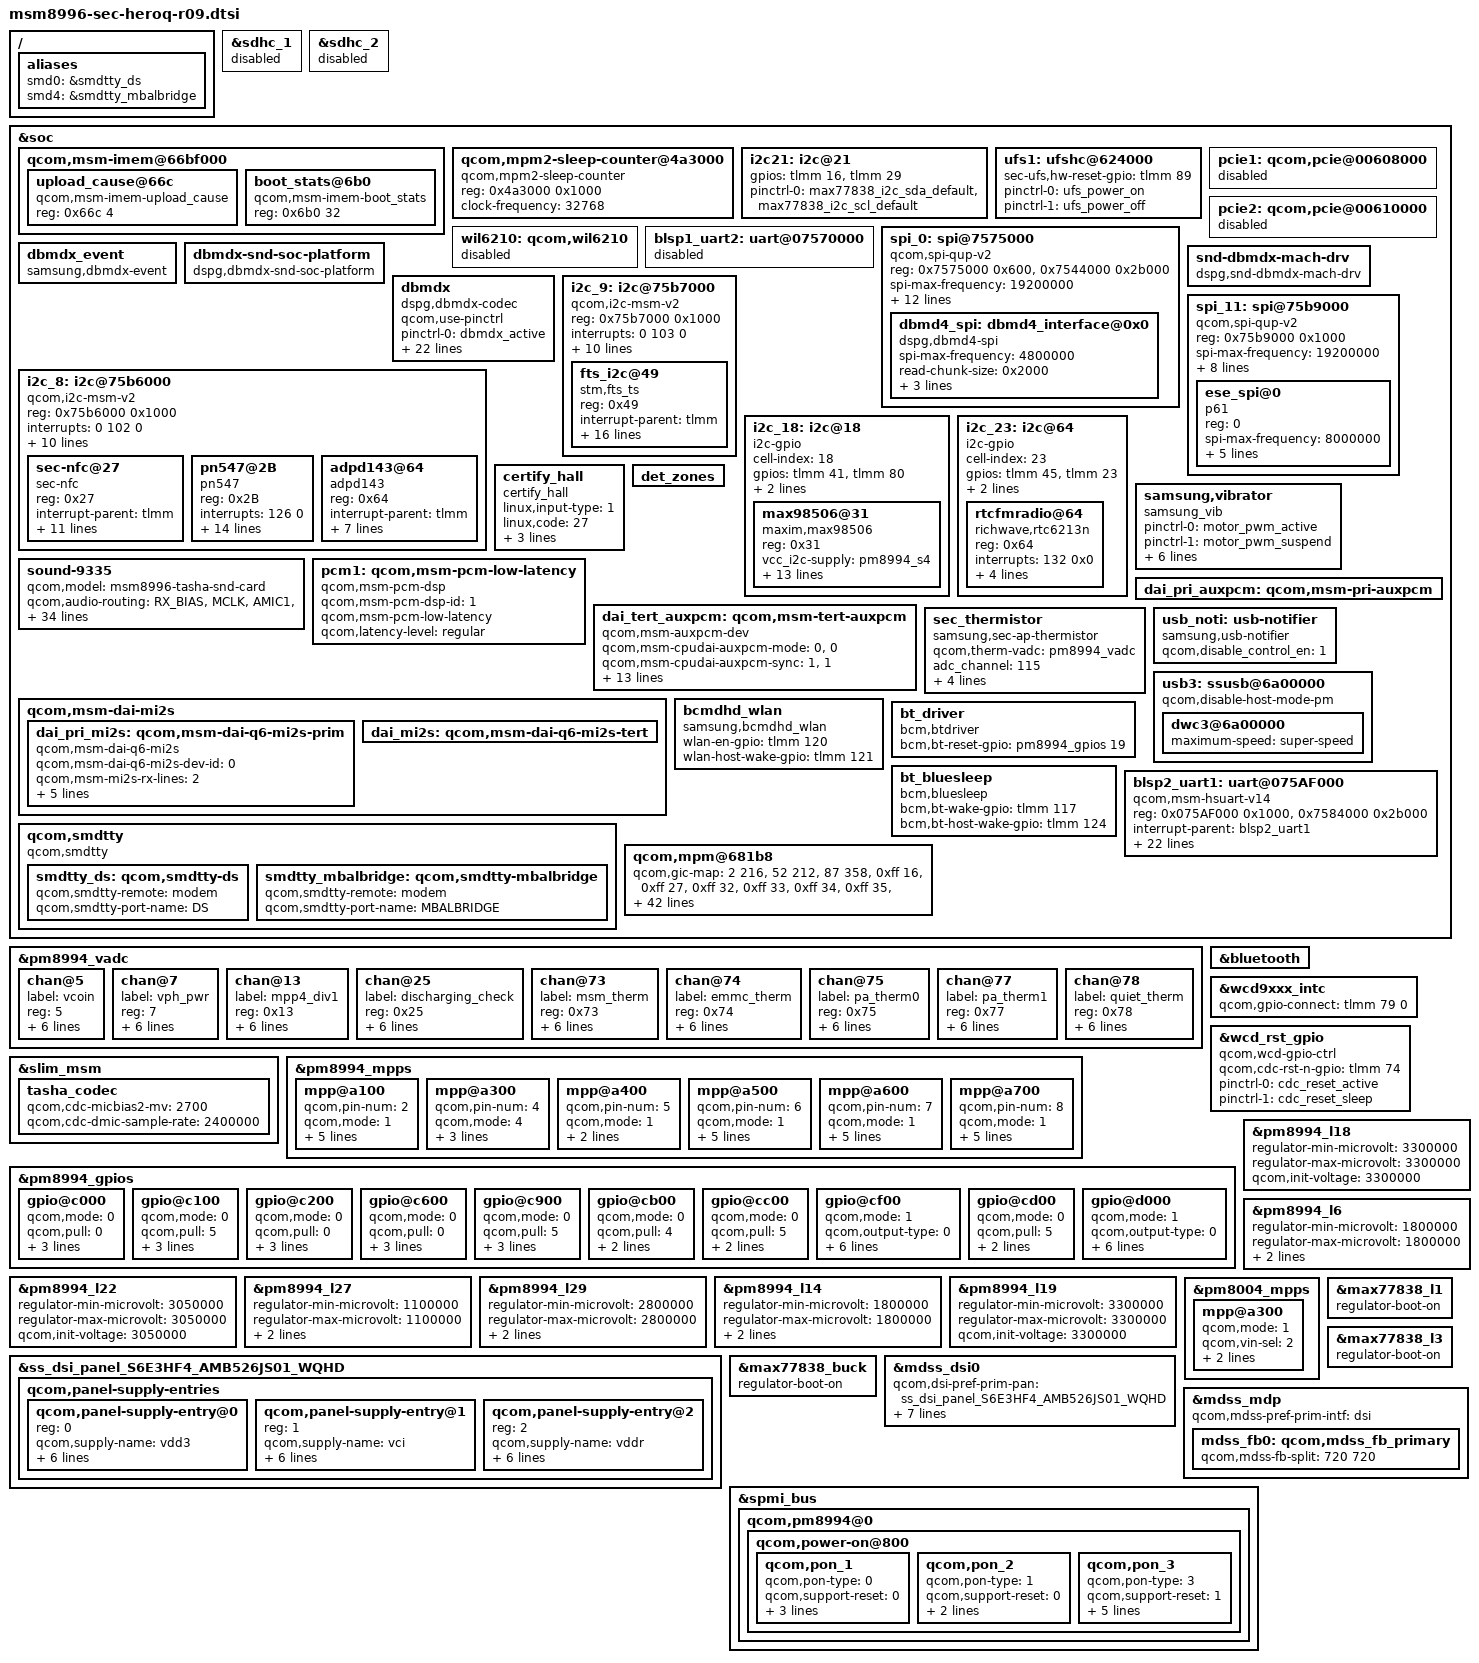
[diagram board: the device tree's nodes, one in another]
/* Copyright (c) 2015, The Linux Foundation. All rights reserved.
 *
 * This program is free software; you can redistribute it and/or modify
 * it under the terms of the GNU General Public License version 2 and
 * only version 2 as published by the Free Software Foundation.
 *
 * This program is distributed in the hope that it will be useful,
 * but WITHOUT ANY WARRANTY; without even the implied warranty of
 * MERCHANTABILITY or FITNESS FOR A PARTICULAR PURPOSE.  See the
 * GNU General Public License for more details.
 */

/*
 * As a general rule, only chipset-specific property overrides should be placed
 * inside this file.
 */

/*
 * Implement here Samsung specific dtsi
 */

#include "msm8996-pinctrl-sec-heroq-r09.dtsi"
#include "msm8996-sec-heroq-battery-r09.dtsi"
#include "msm8996-heroq_fingerprint-sensor_03.dtsi"
#include "msm8996-max77854-heroqlte.dtsi"
#include "msm8996-camera-sensor-heroq-r04.dtsi"
#include "msm8996-heroqlte-mst-r09.dtsi"
/{

	aliases {
		/* smdtty devices */
		smd0 = &smdtty_ds;
		smd4 = &smdtty_mbalbridge;
	};

};
&sdhc_1 {
	status = "disabled";
};
&sdhc_2 {
	status = "disabled";
};

&soc {
	qcom,msm-imem@66bf000 {

		upload_cause@66c { /* CONFIG_SEC_DEBUG */
			compatible = "qcom,msm-imem-upload_cause";
			reg = <0x66c 4>;
		};

		boot_stats@6b0 {
			compatible = "qcom,msm-imem-boot_stats";
			reg = <0x6b0 32>;
		};
	};

	qcom,mpm2-sleep-counter@4a3000 {
		compatible = "qcom,mpm2-sleep-counter";
		reg = <0x4a3000 0x1000>;
		clock-frequency = <32768>;
	};

	/* MAX77838 Display PMIC(PB38) */
	i2c21: i2c@21 {
		gpios = <&tlmm 16 0 /* sda */
			&tlmm 29 0 /* scl */
		>;

		pinctrl-names = "max77838_i2c_pins_default";
		pinctrl-0 = <&max77838_i2c_sda_default &max77838_i2c_scl_default>;
	};

	ufs1: ufshc@624000 {
		sec-ufs,hw-reset-gpio = <&tlmm 89 0x0>;
		pinctrl-names = "ufs_poweron","ufs_poweroff";
		pinctrl-0 = <&ufs_power_on>;
		pinctrl-1 = <&ufs_power_off>;
	};

	pcie1: qcom,pcie@00608000 {
		status = "disabled";
	};

	pcie2: qcom,pcie@00610000 {
		status = "disabled";
	};

	wil6210: qcom,wil6210 {
		status = "disabled";
	};

	blsp1_uart2: uart@07570000 {
		status = "disabled";
	};

	spi_0: spi@7575000 { /* BLSP1 QUP0 */
		compatible = "qcom,spi-qup-v2";
		#address-cells = <1>;
		#size-cells = <0>;
		reg-names = "spi_physical", "spi_bam_physical";
		reg = <0x7575000 0x600>,<0x7544000 0x2b000>;
		spi-max-frequency = <19200000>;
		interrupt-names = "spi_irq", "spi_bam_irq";
		interrupts = <0 95 0>,<0 238 0>;
		qcom,master-id = <86>;
		qcom,use-bam;
		qcom,infinite-mode = <0>;

		qcom,bam-consumer-pipe-index = <12>;
		qcom,bam-producer-pipe-index = <13>;


		qcom,ver-reg-exists;
		qcom,use-pinctrl;
		pinctrl-names = "spi_default", "spi_sleep";
		pinctrl-0 = <&spi_0_active>;
		pinctrl-1 = <&spi_0_sleep>;

		clock-names = "iface_clk", "core_clk";

		clocks = <&clock_gcc clk_gcc_blsp1_ahb_clk>,
			 <&clock_gcc clk_gcc_blsp1_qup1_spi_apps_clk>;

		dbmd4_spi:dbmd4_interface@0x0  {
			compatible = "dspg,dbmd4-spi";
			spi-max-frequency = <4800000>;
			read-chunk-size  = <0x2000> ;
			write-chunk-size = <0x20000> ;
			dma_min_buffer_size = <0>;
			reg = <0>;
		};
	};

	dbmdx_event {
		status = "okay";
		compatible = "samsung,dbmdx-event";
	};

	dbmdx-snd-soc-platform {
		compatible = "dspg,dbmdx-snd-soc-platform";
	};

	snd-dbmdx-mach-drv {
		compatible = "dspg,snd-dbmdx-mach-drv";
	};

	dbmdx {
		status = "okay";
		compatible = "dspg,dbmdx-codec";

		qcom,use-pinctrl;
		pinctrl-names = "dbmdx_default", "dbmdx_sleep";
		pinctrl-0 = <&dbmdx_active>;
		pinctrl-1 = <&dbmdx_sleep>;

		sv-gpio = <&tlmm 42 0>; /* VOICE_INT */
		wakeup-gpio = <&pm8994_mpps 7 0>; /* VOICE_WAKE */
		reset-gpio = <&pm8004_mpps 4 0>; /* VOICE_RST */

		vreg_l27-supply = <&pm8994_l27>;

		auto_buffering = <1>;
		cmd-interface = <&dbmd4_spi>;
		feature-va; /* enable VA */
		/* feature-vqe; */ /* enable VQE */
		/* feature-firmware-overlay; */
		va-firmware-name = "dbmd4_va_fw.bin";
		/* vqe-firmware-name = "dbmd4_vqe_fw.bin"; */
		va-config = <0x80290020
					0x802210E0
					0x80158E8E
					0x801b0020
					0x80230021
					0x80103015>;
		va-speeds = <0x0000 460800   0 960000
					0x0000 2000000 0 4800000
					0x0000 3000000 0 4800000>;
		va-mic-config = <0xf041 0x1044 0x0008>;
		va-mic-mode = <0>;
		/* vqe-config = < >; */
		/* vqe-modes = <0 1 2 3 4 5 0x100>; */
		master-clk-rate = <32768>;
		/* constant-clk-rate = <32768>; */
		auto_detection = <1>;
		detection_buffer_channels = <0>;
		pcm_streaming_mode = <1>;
		firmware_id = <0xdbd4>;
		use_gpio_for_wakeup = <1>; /* Use wakeup gpio */
		wakeup_set_value = <0>;  /* Value to write to wakeup gpio */

	};
/*
	i2c_3: i2c@7577000 { // BLSP1 QUP3
		compatible = "qcom,i2c-msm-v2";
		#address-cells = <1>;
		#size-cells = <0>;
		reg-names = "qup_phys_addr";
		reg = <0x7577000 0x1000>;
		interrupt-names = "qup_irq";
		interrupts = <0 97 0>;
		dmas = <&dma_blsp1 16 32 0x20000020 0x20>,    // or 32 to 64
			<&dma_blsp1 17 32 0x20000020 0x20>;
		dma-names = "tx", "rx";
		qcom,master-id = <86>;
		qcom,clk-freq-out = <400000>;
		qcom,clk-freq-in  = <19200000>;
		clock-names = "iface_clk", "core_clk";
		clocks = <&clock_gcc clk_gcc_blsp1_ahb_clk>,
			<&clock_gcc clk_gcc_blsp1_qup3_i2c_apps_clk>;
		pinctrl-names = "i2c_active", "i2c_sleep";
		pinctrl-0 = <&i2c_3_active>;
		pinctrl-1 = <&i2c_3_sleep>;
		qcom,disable-dma;
	};
*/
	i2c_9: i2c@75b7000 { /* BLSP1 QUP9 */
		compatible = "qcom,i2c-msm-v2";
		#address-cells = <1>;
		#size-cells = <0>;
		reg-names = "qup_phys_addr";
		reg = <0x75b7000 0x1000>;
		interrupt-names = "qup_irq";
		interrupts = <0 103 0>;
		dmas = <&dma_blsp2 16 32 0x20000020 0x20>,    // or 32 to 64
		<&dma_blsp2 17 32 0x20000020 0x20>;
		dma-names = "tx", "rx";
		qcom,master-id = <84>;
		qcom,clk-freq-out = <400000>;
		qcom,clk-freq-in  = <19200000>;
		clock-names = "iface_clk", "core_clk";
		clocks = <&clock_gcc clk_gcc_blsp2_ahb_clk>,
		<&clock_gcc clk_gcc_blsp2_qup3_i2c_apps_clk>;
		pinctrl-names = "i2c_active", "i2c_sleep";
		pinctrl-0 = <&i2c_9_active>;
		pinctrl-1 = <&i2c_9_sleep>;
		qcom,disable-dma;
	};

	/* NFC */
	i2c_8: i2c@75b6000 { /* BLSP2 QUP1 */
		compatible = "qcom,i2c-msm-v2";
		#address-cells = <1>;
		#size-cells = <0>;
		reg-names = "qup_phys_addr";
		reg = <0x75b6000 0x1000>;
		interrupt-names = "qup_irq";
		interrupts = <0 102 0>;
		dmas = <&dma_blsp2 14 32 0x20000020 0x20>,
			<&dma_blsp2 15 32 0x20000020 0x20>;
		dma-names = "tx", "rx";
		qcom,master-id = <84>;
		qcom,clk-freq-out = <400000>;
		qcom,clk-freq-in  = <19200000>;
		clock-names = "iface_clk", "core_clk";
		clocks = <&clock_gcc clk_gcc_blsp2_ahb_clk>,
			<&clock_gcc clk_gcc_blsp2_qup2_i2c_apps_clk>;
		pinctrl-names = "i2c_active", "i2c_sleep";
		pinctrl-0 = <&i2c_8_active>;
		pinctrl-1 = <&i2c_8_sleep>;
		qcom,disable-dma;

		sec-nfc@27 {
			compatible = "sec-nfc";
			reg = <0x27>;
			interrupt-parent = <&tlmm>;
			interrupts = <126 0>;
			pinctrl-names = "nfc_active","nfc_suspend";
			pinctrl-0 = <&nfc_int_active &nfc_enable_active &nfc_firmware_active>;
			pinctrl-1 = <&nfc_int_suspend &nfc_enable_suspend &nfc_firmware_suspend>;
			sec-nfc,ven-gpio = <&tlmm 62 0x0>;
			sec-nfc,firm-gpio = <&tlmm 63 0x0>;
			sec-nfc,irq-gpio = <&tlmm 126 0x01>;
			clocks = <&clock_gcc clk_bb_clk2_pin>;
			clock-names = "nfc_clock";
			sec-nfc,i2c_1p8 = <&pm8994_l6>;
			qcom,clk-src="BBCLK2";
		};
		pn547@2B {
			compatible = "pn547";
			reg = <0x2B>;

			interrupts = <126 0>;
			interrupt-parent = <&tlmm>;

			pinctrl-names = "nfc_active","nfc_suspend";
			pinctrl-0 = <&nfc_int_active &nfc_enable_active &nfc_firmware_active>;
			pinctrl-1 = <&nfc_int_suspend &nfc_enable_suspend &nfc_firmware_suspend>;

			pn547,ven-gpio = <&tlmm 62 0x0>;
			pn547,firm-gpio = <&tlmm 63 0x0>;
			pn547,irq-gpio = <&tlmm 126 0x01>;
			pn547,clk_req-gpio = <&pm8994_gpios 10 0>;
			pn547,pwr_req = <&pm8994_mpps 6 0>;
			pn547,i2c_1p8 = <&pm8994_l6>;
			pn547,ldo_flag = <1>;
			clocks = <&clock_gcc clk_bb_clk2_pin>;
			clock-names = "nfc_clock";
			qcom,clk-src="BBCLK2";
		};
		adpd143@64 {
			compatible = "adpd143";
			reg = <0x64>;
			interrupt-parent = <&tlmm>;
			interrupts = <119 0>;
			pinctrl-names = "sleep", "idle";
			pinctrl-0 = <&hrm_int_suspend>;
			pinctrl-1 = <&hrm_int_active>;
			adpd143,irq_gpio = <&tlmm 119 0x00>;
			adpd143_1p8-supply = <&pm8994_lvs1>;
			adpd143_3p3-supply = <&pm8994_l19>;
			adpd143,use-sub-pmic = <0>;
		};
	};

	spi_11: spi@75b9000 { /* BLSP2 QUP4 */
		compatible = "qcom,spi-qup-v2";
		#address-cells = <1>;
		#size-cells = <0>;
		reg-names = "spi_physical";
		reg = <0x75b9000 0x1000>;
		spi-max-frequency = <19200000>;
		interrupt-names = "spi_irq";
		interrupts = <0 105 0>;
		qcom,master-id = <84>;

		qcom,ver-reg-exists;
		qcom,use-pinctrl;
		pinctrl-names = "spi_default", "spi_sleep";
		pinctrl-0 = <&spi_11_active>;
		pinctrl-1 = <&spi_11_sleep>;

		clock-names = "iface_clk", "core_clk";

		clocks = <&clock_gcc clk_gcc_blsp2_ahb_clk>,
			 <&clock_gcc clk_gcc_blsp2_qup5_spi_apps_clk>;
	    ese_spi@0 {
			compatible = "p61";
		    reg = <0>;
		    spi-max-frequency = <8000000>;

		    gpio-controller;
		    #gpio-cells = <2>;

		    p61-mosipin = <&tlmm 58 0x0>;
		    p61-misopin = <&tlmm 59 0x0>;
		    p61-cspin = <&tlmm 60 0x0>;
		    p61-clkpin = <&tlmm 61 0x0>;

		};
	};

	i2c_18: i2c@18 { /* max98506 amp */
		cell-index = <18>;
		compatible = "i2c-gpio";
		gpios = <&tlmm 41 0 /* sda */
			&tlmm 80 0 /* scl */
		>;
		i2c-gpio,delay-us = <2>;
		#address-cells = <1>;
		#size-cells = <0>;
		pinctrl-names = "default";
		pinctrl-0 = <&max98506_i2c_default>;

		max98506@31 {
			compatible = "maxim,max98506";
			reg = <0x31>;
			vcc_i2c-supply = <&pm8994_s4>;
			maxim,i2c-pull-up;
			maxim,platform_type = <1>;
			maxim,spk-gain= <0x14>;
			maxim,sysclk = <12288000>;
			maxim,vmon_slot = <1>;
			maxim,irq-gpio = <&pm8994_gpios 14 0x1>;
			maxim,platform_info = <1 0x1000 0x10001062 0x0FF1020B 0x00000000 41>;
			maxim,boost_step = <
				0x0F 0x0F 0x0F 0x0F
				0x0F 0x0F 0x0F 0x0F
				0x0F 0x0F 0x0F 0x0F
				0x0F 0x0F 0x02 0x00
			>;
			maxim,adc_threshold = <7>;
			maxim,registers-of-amp =
				<0x1F 0x00>,
				<0x21 0xC0>,
				<0x2F 0x00>;
		};
	};

	i2c_23: i2c@64{ /* FM Radio (Richwave) */
		cell-index = <23>;
		compatible = "i2c-gpio";

		gpios = <&tlmm 45 0 /* sda */
			&tlmm 23 0 /* scl */
		>;
		i2c-gpio,delay-us = <2>;
		#address-cells = <1>;
		#size-cells = <0>;
		status = "okay";
		pinctrl-names = "default";
		pinctrl-0 = <&fmradio_i2c_default>;

		rtcfmradio@64 {
			compatible = "richwave,rtc6213n", "rtc6213n";
			reg = <0x64>;
			interrupts = <132 0x0>;
			interrupt-parent = <&tlmm>;
			pinctrl-names = "default";
			pinctrl-0 = <&fmradio_int_active &fmradio_int_suspend>;
			fmint-gpio = <&tlmm 132 0>; /* FM_INT */
		};
	};

	certify_hall {
		compatible = "certify_hall";
		linux,input-type = <1>;
		linux,code = <27>;
		certify_hall,gpio_certify_cover = <&pm8994_gpios 7 0x1>;
		debounce-interval = <15>;
	};

	samsung,vibrator {
		compatible = "samsung_vib";
		pinctrl-names = "tlmm_motor_active","tlmm_motor_suspend";
		pinctrl-0 = <&motor_pwm_active>;
		pinctrl-1 = <&motor_pwm_suspend>;
		samsung,vib_pwm = <&tlmm 57 0>;
		samsung,gp_clk = <0x00364000>;   // Address of GP1 clock
		samsung,chip_model = <0>;         // using max77854 driver
		samsung,m_default = <2>;
		samsung,n_default = <92>;
		samsung,motor_strength = <94>;
		status = "ok";
	};

	det_zones: det_zones {
		#list-det-cells = <2>;
	};

	sound-9335 {
		qcom,model = "msm8996-tasha-snd-card";

		qcom,audio-routing =
			"RX_BIAS", "MCLK",
			"AMIC1", "MIC BIAS4",
			"MIC BIAS4", "Third Mic",
			"AMIC2", "MIC BIAS2",
			"MIC BIAS2", "Headset Mic",
			"AMIC3", "MIC BIAS2",
			"MIC BIAS2", "FM Tx",
			"DMIC0", "MIC BIAS1",
			"MIC BIAS1", "Digital Mic0",
			"DMIC2", "MIC BIAS3",
			"MIC BIAS3", "Digital Mic2";

		qcom,msm-mbhc-hphl-swh = <1>;
		qcom,msm-mbhc-gnd-swh = <1>;
		qcom,mpp-channel-scaling = <4 1 1>;
		qcom,det_debounce_time_ms = <100>;
		qcom,earjack-read-vadc = <&pm8994_vadc>;

		asoc-cpu = <&dai_pri_auxpcm>, <&dai_tert_auxpcm>, <&dai_pri_mi2s>, <&dai_mi2s>,
				<&sb_0_rx>, <&sb_0_tx>, <&sb_1_rx>, <&sb_1_tx>,
				<&sb_2_rx>, <&sb_2_tx>, <&sb_3_rx>, <&sb_3_tx>,
				<&sb_4_rx>, <&sb_4_tx>, <&sb_5_tx>, <&afe_pcm_rx>,
				<&afe_pcm_tx>, <&afe_proxy_rx>, <&afe_proxy_tx>,
				<&incall_record_rx>, <&incall_record_tx>,
				<&incall_music_rx>, <&incall_music2_rx>,
				<&sb_5_rx>;
		asoc-cpu-names = "msm-dai-q6-auxpcm.1", "msm-dai-q6-auxpcm.3",
				"msm-dai-q6-mi2s.0", "msm-dai-q6-mi2s.2",
				"msm-dai-q6-dev.16384", "msm-dai-q6-dev.16385",
				"msm-dai-q6-dev.16386", "msm-dai-q6-dev.16387",
				"msm-dai-q6-dev.16388", "msm-dai-q6-dev.16389",
				"msm-dai-q6-dev.16390", "msm-dai-q6-dev.16391",
				"msm-dai-q6-dev.16392", "msm-dai-q6-dev.16393",
				"msm-dai-q6-dev.16395", "msm-dai-q6-dev.224",
				"msm-dai-q6-dev.225", "msm-dai-q6-dev.241",
				"msm-dai-q6-dev.240", "msm-dai-q6-dev.32771",
				"msm-dai-q6-dev.32772", "msm-dai-q6-dev.32773",
				"msm-dai-q6-dev.32770", "msm-dai-q6-dev.16394";

		det-zones-list = <&det_zones 0 2>,
				 <&det_zones 690 2>,
				 <&det_zones 691 1>,
				 <&det_zones 9999 1>;

		/delete-property/qcom,hdmi-audio-rx;
		/delete-property/qcom,hph-en0-gpio;
		/delete-property/qcom,us-euro-gpios;
		/delete-property/qcom,wsa-max-devs;
		/delete-property/qcom,wsa-devs;
		/delete-property/qcom,wsa-aux-dev-prefix;
	};

	pcm1: qcom,msm-pcm-low-latency {
		compatible = "qcom,msm-pcm-dsp";
		qcom,msm-pcm-dsp-id = <1>;
		qcom,msm-pcm-low-latency;
		qcom,latency-level = "regular";
	};

	dai_pri_auxpcm: qcom,msm-pri-auxpcm {
		/delete-property/ pinctrl-names;
		/delete-property/ pinctrl-0;
		/delete-property/ pinctrl-1;
	};

	dai_tert_auxpcm: qcom,msm-tert-auxpcm {
		compatible = "qcom,msm-auxpcm-dev";
		qcom,msm-cpudai-auxpcm-mode = <0>, <0>;
		qcom,msm-cpudai-auxpcm-sync = <1>, <1>;
		qcom,msm-cpudai-auxpcm-frame = <5>, <4>;
		qcom,msm-cpudai-auxpcm-quant = <2>, <2>;
		qcom,msm-cpudai-auxpcm-num-slots = <1>, <1>;
		qcom,msm-cpudai-auxpcm-slot-mapping = <1>, <1>;
		qcom,msm-cpudai-auxpcm-data = <0>, <0>;
		qcom,msm-cpudai-auxpcm-pcm-clk-rate = <2048000>, <2048000>;
		qcom,msm-auxpcm-interface = "tertiary";
		qcom,msm-cpudai-afe-clk-ver = <2>;
		pinctrl-names = "default", "sleep";
		pinctrl-0 = <&tert_aux_pcm_active &tert_aux_pcm_din_active>;
		pinctrl-1 = <&tert_aux_pcm_sleep &tert_aux_pcm_din_sleep>;
	};

	qcom,msm-dai-mi2s {
		dai_pri_mi2s: qcom,msm-dai-q6-mi2s-prim {
			compatible = "qcom,msm-dai-q6-mi2s";
			qcom,msm-dai-q6-mi2s-dev-id = <0>;
			qcom,msm-mi2s-rx-lines = <2>;
			qcom,msm-mi2s-tx-lines = <1>;
			pinctrl-names = "default", "sleep";
			pinctrl-0 = <&pri_mi2s_active &pri_mi2s_sd0_active &pri_mi2s_sd1_active>;
			pinctrl-1 = <&pri_mi2s_sleep &pri_mi2s_sd0_sleep &pri_mi2s_sd1_sleep>;
		};

		dai_mi2s: qcom,msm-dai-q6-mi2s-tert {
			/delete-property/ pinctrl-names;
			/delete-property/ pinctrl-0;
			/delete-property/ pinctrl-1;
		};
	};

	sec_thermistor {
		compatible = "samsung,sec-ap-thermistor";
		qcom,therm-vadc = <&pm8994_vadc>;
		status = "okay";
		adc_channel = <115>;
		adc_array = <25799 25825 25852 25879 25906 25933 25991 26050
				  	 26109 26168 26227 26264 26301 26338 26375 26413
				  	 26492 26571 26651 26730 26810 26882 26954 27026
				  	 27098 27170 27256 27343 27430 27517 27604 27700
				  	 27797 27893 27990 28087 28229 28371 28513 28655
				  	 28797 28856 28915 28975 29034 29094 29301 29508
				  	 29715 29922 30130 30325 30520 30715 30910 31105
				  	 31353 31602 31851 32100 32349 32491 32633 32776
				  	 32918 33061 33246 33431 33616 33801 33986 34214
				  	 34443 34672 34901 35130 35395 35660 35926 36191
				  	 36457 36671 36885 37099 37313 37528 37734 37941
				  	 38148 38355 38562 38741 38920 39099 39278 39457
				  	 39585 39714 39842 39971 40100 40213 40327 40441
				  	 40555 40669 40714 40759 40805 40850 40896 >;

		temp_array = <900 890 880 870 860 850 840 830 820 810
			800 790 780 770 760 750 740 730 720 710
			700 690 680 670 660 650 640 630 620 610
			600 590 580 570 560 550 540 530 520 510
			500 490 480 470 460 450 440 430 420 410
			400 390 380 370 360 350 340 330 320 310
			300 290 280 270 260 250 240 230 220 210
			200 190 180 170 160 150 140 130 120 110
			100 90 80 70 60 50 40 30 20 10
			0 (-10) (-20) (-30) (-40) (-50) (-60) (-70) (-80) (-90)
			(-100)(-110)(-120)(-130)(-140)(-150)(-160)(-170)(-180)(-190)
			(-200)>;
	};

	usb_noti: usb-notifier {
		compatible = "samsung,usb-notifier";
		qcom,disable_control_en = <1>;
	};

	usb3: ssusb@6a00000{
		qcom,disable-host-mode-pm;
		dwc3@6a00000 {
			maximum-speed = "super-speed";
		};
	};

	bcmdhd_wlan {
		compatible = "samsung,bcmdhd_wlan";
		wlan-en-gpio = <&tlmm 120 0>;
		wlan-host-wake-gpio = <&tlmm 121 0>;
		/*pinctrl-name = "default";
		pinctrl-0 = <&bcmdhd_default>;*/
		status = "ok";
	};

	bt_driver {
		compatible = "bcm,btdriver";
		bcm,bt-reset-gpio = <&pm8994_gpios 19 0>;
		status = "ok";
	};

	bt_bluesleep {
		compatible = "bcm,bluesleep";
		/*
		pinctrl-names = "bt_wake_default","bt_wake_active","bt_wake_suspend",
						"host_wake_default","host_wake_active","host_wake_suspend";
		pinctrl-0 = <&bt_wake_default_s>;
		pinctrl-1 = <&bt_wake_active_s>;
		pinctrl-2 = <&bt_wake_suspend_s>;
		pinctrl-3 = <&host_wake_default_s>;
		pinctrl-4 = <&host_wake_active_s>;
		pinctrl-5 = <&host_wake_suspend_s>;
		*/
		bcm,bt-wake-gpio = <&tlmm 117 0>;
		bcm,bt-host-wake-gpio = <&tlmm 124 0>;
		status = "ok";
	};

	/* BLSP2 UART1 */
	blsp2_uart1: uart@075AF000 {
		compatible = "qcom,msm-hsuart-v14";
		reg = <0x075AF000 0x1000>,
		    <0x7584000 0x2b000>;
		status = "ok";
		reg-names = "core_mem", "bam_mem";
		interrupt-names = "core_irq", "bam_irq";
		#address-cells = <0>;
		interrupt-parent = <&blsp2_uart1>;
		interrupts = <0 1>;
		#interrupt-cells = <1>;
		interrupt-map-mask = <0xffffffff>;
		interrupt-map = <0 &intc 0 0 113 0
			    1 &intc 0 0 239 0>;

		qcom,bam-tx-ep-pipe-index = <0>;
		qcom,bam-rx-ep-pipe-index = <1>;
		qcom,master-id = <84>;
		clock-names = "core_clk", "iface_clk";
		clocks = <&clock_gcc clk_gcc_blsp2_uart1_apps_clk>,
		    <&clock_gcc clk_gcc_blsp2_ahb_clk>;

		qcom,tx-gpio = <&tlmm 53 0>;
		qcom,rx-gpio = <&tlmm 54 0>;
		qcom,cts-gpio = <&tlmm 55 0>;
		qcom,rfr-gpio = <&tlmm 56 0>;

		pinctrl-names = "sleep", "default";
		pinctrl-0 = <&blsp2_uart1_sleep>;
		pinctrl-1 = <&blsp2_uart1_active>;

		qcom,msm-bus,name = "blsp2_uart1";
		qcom,msm-bus,num-cases = <2>;
		qcom,msm-bus,num-paths = <1>;
		qcom,msm-bus,vectors-KBps =
			    <84 512 0 0>,
			    <84 512 500 800>;
		qcom,msm-obs;
	};

	qcom,smdtty {
		compatible = "qcom,smdtty";

		smdtty_ds: qcom,smdtty-ds {
			qcom,smdtty-remote = "modem";
			qcom,smdtty-port-name = "DS";
		};

		smdtty_mbalbridge: qcom,smdtty-mbalbridge {
			qcom,smdtty-remote = "modem";
			qcom,smdtty-port-name = "MBALBRIDGE";
		};
	};

	qcom,mpm@681b8 {
		qcom,gic-map = <2 216>, /* tsens_upper_lower_int */
			<52 212>,   /* qmp_usb3_lfps_rxterm_irq */
			<87 358>,   /* ee0_krait_hlos_spmi_periph_irq */
			<0xff 16>,  /* APCj_qgicdrCpu0HwFaultIrptReq */
			<0xff 27>,  /* APCj_qgicdrCpu0QTmrVirtIrptReq */
			<0xff 32>,
			<0xff 33>,  /* APCC_qgicL2PerfMonIrptReq */
			<0xff 34>,  /* APCC_qgicL2ErrorIrptReq */
			<0xff 35>,  /* WDT_barkInt */
			<0xff 40>,  /* qtimer_phy_irq */
			<0xff 41>,  /* APCj_qgicdrL2HwFaultNonFatalIrptReq */
			<0xff 42>,  /* APCj_qgicdrL2HwFaultFatalIrptReq */
			<0xff 49>,  /* L3UX_qgicL3ErrorIrptReq */
			<0xff 54>,  /* M4M_sysErrorInterrupt */
			<0xff 55>,  /* M4M_sysDlmInterrupt */
			<0xff 57>,  /* mss_to_apps_irq(0) */
			<0xff 58>,  /* mss_to_apps_irq(1) */
			<0xff 59>,  /* mss_to_apps_irq(2) */
			<0xff 60>,  /* mss_to_apps_irq(3) */
			<0xff 61>,  /* mss_a2_bam_irq */
			<0xff 62>,  /* QTMR_qgicFrm0VirtIrq */
			<0xff 63>,  /* QTMR_qgicFrm1PhysIrq */
			<0xff 64>,  /* QTMR_qgicFrm2PhysIrq */
			<0xff 65>,  /* QTMR_qgicFrm3PhysIrq */
			<0xff 66>,  /* QTMR_qgicFrm4PhysIrq */
			<0xff 67>,  /* QTMR_qgicFrm5PhysIrq */
			<0xff 68>,  /* QTMR_qgicFrm6PhysIrq */
			<0xff 69>,  /* QTMR_qgicFrm7PhysIrq */
			<0xff 70>,  /* iommu_pmon_nonsecure_irq */
			<0xff 74>,  /* osmmu_CIrpt[1] */
			<0xff 75>,  /* osmmu_CIrpt[0] */
			<0xff 77>,  /* osmmu_CIrpt[0] */
			<0xff 78>,  /* osmmu_CIrpt[0] */
			<0xff 79>,  /* osmmu_CIrpt[0] */
			<0xff 80>,  /* CPR3_irq */
			<0xff 94>,  /* osmmu_CIrpt[0] */
			<0xff 97>,  /* iommu_nonsecure_irq */
			<0xff 99>,  /* msm_iommu_pmon_nonsecure_irq */
			<0xff 102>, /* osmmu_CIrpt[1] */
			<0xff 105>, /* iommu_pmon_nonsecure_irq */
			<0xff 108>, /* osmmu_PMIrpt */
			<0xff 109>, /* ocmem_dm_nonsec_irq */
			<0xff 110>, /* csiphy_0_irq */
			<0xff 111>, /* csiphy_1_irq */
			<0xff 112>, /* csiphy_2_irq */
			<0xff 115>, /* mdss_irq */
			<0xff 126>, /* bam_irq[0] */
			<0xff 127>, /* blsp1_qup_irq(0) */
			<0xff 128>, /* blsp1_qup_irq(1) */
			<0xff 129>, /* blsp1_qup_irq(2) */
			<0xff 132>, /* blsp1_qup_irq(5) */
			<0xff 133>, /* blsp2_qup_irq(0) */
			<0xff 134>, /* blsp2_qup_irq(1) */
			<0xff 135>, /* blsp2_qup_irq(2) */
			<0xff 136>, /* blsp2_qup_irq(3) */
			<0xff 137>, /* blsp2_qup_irq(4) */
			<0xff 138>, /* blsp2_qup_irq(5) */
			<0xff 140>, /* blsp1_uart_irq(1) */
			<0xff 145>, /* blsp2_uart_irq(0) */
			<0xff 146>, /* blsp2_uart_irq(1) */
			<0xff 155>, /* sdcc_irq[0] */
			<0xff 157>, /* sdc2_irq[0] */
			<0xff 163>, /* usb30_ee1_irq */
			<0xff 164>, /* usb30_bam_irq(0) */
			<0xff 165>, /* usb30_hs_phy_irq */
			<0xff 166>, /* sdc1_pwr_cmd_irq */
			<0xff 170>, /* sdcc_pwr_cmd_irq */
			<0xff 173>, /* sdc1_irq[0] */
			<0xff 174>, /* o_wcss_apss_smd_med */
			<0xff 175>, /* o_wcss_apss_smd_low */
			<0xff 176>, /* o_wcss_apss_smsm_irq */
			<0xff 177>, /* o_wcss_apss_wlan_data_xfer_done */
			<0xff 178>, /* o_wcss_apss_wlan_rx_data_avail */
			<0xff 179>, /* o_wcss_apss_asic_intr */
			<0xff 180>, /* pcie20_2_int_pls_err */
			<0xff 181>, /* wcnss watchdog */
			<0xff 188>, /* lpass_irq_out_apcs(0) */
			<0xff 189>, /* lpass_irq_out_apcs(1) */
			<0xff 190>, /* lpass_irq_out_apcs(2) */
			<0xff 191>, /* lpass_irq_out_apcs(3) */
			<0xff 192>, /* lpass_irq_out_apcs(4) */
			<0xff 193>, /* lpass_irq_out_apcs(5) */
			<0xff 194>, /* lpass_irq_out_apcs(6) */
			<0xff 195>, /* lpass_irq_out_apcs(7) */
			<0xff 196>, /* lpass_irq_out_apcs(8) */
			<0xff 197>, /* lpass_irq_out_apcs(9) */
			<0xff 198>, /* coresight-tmc-etr interrupt */
			<0xff 200>, /* rpm_ipc(4) */
			<0xff 201>, /* rpm_ipc(5) */
			<0xff 202>, /* rpm_ipc(6) */
			<0xff 203>, /* rpm_ipc(7) */
			<0xff 204>, /* rpm_ipc(24) */
			<0xff 205>, /* rpm_ipc(25) */
			<0xff 206>, /* rpm_ipc(26) */
			<0xff 207>, /* rpm_ipc(27) */
			<0xff 208>,
			<0xff 210>,
			<0xff 211>, /* usb_dwc3_otg */
			<0xff 215>, /* o_bimc_intr(0) */
			<0xff 224>, /* spdm_realtime_irq[1] */
			<0xff 238>, /* crypto_bam_irq[0] */
			<0xff 240>, /* summary_irq_kpss */
			<0xff 253>, /* sdc2_pwr_cmd_irq */
			<0xff 258>, /* lpass_irq_out_apcs[21] */
			<0xff 268>, /* bam_irq[1] */
			<0xff 270>, /* bam_irq[0] */
			<0xff 271>, /* bam_irq[0] */
			<0xff 276>, /* wlan_pci */
			<0xff 280>, /* pcie20_0_intd */
			<0xff 283>, /* pcie20_0_int_pls_err */
			<0xff 284>, /* pcie20_0_int_aer_legacy */
			<0xff 286>, /* pcie20_0_int_pls_link_down */
			<0xff 290>, /* ufs_ice_nonsec_level_irq */
			<0xff 293>, /* pcie20_2_int_pls_link_down */
			<0xff 295>, /* camss_cpp_mmu_cirpt[0] */
			<0xff 296>, /* camss_cpp_mmu_pmirpt */
			<0xff 297>, /* ufs_intrq */
			<0xff 298>, /* arm-smmu-context-fault */
			<0xff 302>, /* qdss_etrbytecnt_irq */
			<0xff 310>, /* pcie20_1_int_pls_err */
			<0xff 311>, /* pcie20_1_int_aer_legacy */
			<0xff 313>, /* pcie20_1_int_pls_link_down */
			<0xff 318>, /* venus0_mmu_pmirpt */
			<0xff 319>, /* venus0_irq */
			<0xff 325>, /* camss_irq18 */
			<0xff 326>, /* camss_irq0 */
			<0xff 327>, /* camss_irq1 */
			<0xff 328>, /* camss_irq2 */
			<0xff 329>, /* camss_irq3 */
			<0xff 330>, /* camss_irq4 */
			<0xff 331>, /* camss_irq5 */
			<0xff 332>, /* sps */
			<0xff 341>, /* camss_irq6 */
			<0xff 346>, /* camss_irq8 */
			<0xff 347>, /* camss_irq9 */
			<0xff 352>, /* mdss_mmu_cirpt[0] */
			<0xff 353>, /* mdss_mmu_cirpt[1] */
			<0xff 361>, /* ogpu_mmu_cirpt[0] */
			<0xff 362>, /* ogpu_mmu_cirpt[1] */
			<0xff 365>, /* ipa_irq[0] */
			<0xff 366>, /* ogpu_mmu_pmirpt */
			<0xff 367>, /* venus0_mmu_cirpt[0] */
			<0xff 368>, /* venus0_mmu_cirpt[1] */
			<0xff 369>, /* venus0_mmu_cirpt[2] */
			<0xff 370>, /* venus0_mmu_cirpt[3] */
			<0xff 375>, /* camss_vfe_mmu_cirpt[0] */
			<0xff 376>, /* camss_vfe_mmu_cirpt[1] */
			<0xff 380>, /* mdss_dma_mmu_cirpt[0] */
			<0xff 381>, /* mdss_dma_mmu_cirpt[1] */
			<0xff 385>, /* mdss_dma_mmu_pmirpt */
			<0xff 387>, /* osmmu_CIrpt[0] */
			<0xff 394>, /* osmmu_PMIrpt */
			<0xff 403>, /* osmmu_PMIrpt */
			<0xff 405>, /* osmmu_CIrpt[0] */
			<0xff 413>, /* osmmu_PMIrpt */
			<0xff 422>, /* ssc_irq_out_apcs[5] */
			<0xff 424>, /* ipa_irq[2] */
			<0xff 425>, /* lpass_irq_out_apcs[22] */
			<0xff 426>, /* lpass_irq_out_apcs[23] */
			<0xff 427>, /* lpass_irq_out_apcs[24] */
			<0xff 428>, /* lpass_irq_out_apcs[25] */
			<0xff 429>, /* lpass_irq_out_apcs[26] */
			<0xff 430>, /* lpass_irq_out_apcs[27] */
			<0xff 431>, /* lpass_irq_out_apcs[28] */
			<0xff 432>, /* lpass_irq_out_apcs[29] */
			<0xff 436>, /* lpass_irq_out_apcs[37] */
			<0xff 437>, /* pcie20_0_int_msi_dev0 */
			<0xff 445>, /* pcie20_1_int_msi_dev0 */
			<0xff 453>, /* pcie20_2_int_msi_dev0 */
			<0xff 461>, /* o_vmem_nonsec_irq */
			<0xff 462>, /* tsens1_tsens_critical_int */
			<0xff 464>, /* ipa_bam_irq[0] */
			<0xff 465>, /* ipa_bam_irq[2] */
			<0xff 477>, /* tsens0_tsens_critical_int */
			<0xff 480>, /* q6_wdog_expired_irq */
			<0xff 481>, /* mss_ipc_out_irq(4) */
			<0xff 483>, /* mss_ipc_out_irq(6) */
			<0xff 484>, /* mss_ipc_out_irq(7) */
			<0xff 487>, /* mss_ipc_out_irq(30) */
			<0xff 490>, /* tsens0_tsens_upper_lower_int */
			<0xff 493>; /* sdc1_ice_nonsec_level_irq */
	};
};

&blsp1_uart2 { /* pinctrl for gpio41 is duplicated - max98506 */
	/delete-property/ pinctrl-names;
	/delete-property/ pinctrl-0;
	/delete-property/ pinctrl-1;
};

&pm8994_vadc {
	chan@5 {
		label = "vcoin";
		reg = <5>;
		qcom,decimation = <0>;
		qcom,pre-div-channel-scaling = <1>;
		qcom,calibration-type = "absolute";
		qcom,scale-function = <0>;
		qcom,hw-settle-time = <0>;
		qcom,fast-avg-setup = <0>;
	};

	chan@7 {
		label = "vph_pwr";
		reg = <7>;
		qcom,decimation = <0>;
		qcom,pre-div-channel-scaling = <1>;
		qcom,calibration-type = "absolute";
		qcom,scale-function = <0>;
		qcom,hw-settle-time = <0>;
		qcom,fast-avg-setup = <0>;
	};

	chan@13 {
		label = "mpp4_div1";
		reg = <0x13>;
		qcom,decimation = <0>;
		qcom,pre-div-channel-scaling = <0>;
		qcom,calibration-type = "absolute";
		qcom,scale-function = <0>;
		qcom,hw-settle-time = <0>;
		qcom,fast-avg-setup = <0>;
	};

	chan@25 {
		label = "discharging_check";
		reg = <0x25>;
		qcom,decimation = <0>;
		qcom,pre-div-channel-scaling = <1>;
		qcom,calibration-type = "ratiometric";
		qcom,scale-function = <0>;
		qcom,hw-settle-time = <0>;
		qcom,fast-avg-setup = <0>;
	};

	chan@73 {
		label = "msm_therm";
		reg = <0x73>;
		qcom,decimation = <0>;
		qcom,pre-div-channel-scaling = <0>;
		qcom,calibration-type = "ratiometric";
		qcom,scale-function = <2>;
		qcom,hw-settle-time = <2>;
		qcom,fast-avg-setup = <0>;
	};

	chan@74 {
		label = "emmc_therm";
		reg = <0x74>;
		qcom,decimation = <0>;
		qcom,pre-div-channel-scaling = <0>;
		qcom,calibration-type = "ratiometric";
		qcom,scale-function = <2>;
		qcom,hw-settle-time = <2>;
		qcom,fast-avg-setup = <0>;
	};

	chan@75 {
		label = "pa_therm0";
		reg = <0x75>;
		qcom,decimation = <0>;
		qcom,pre-div-channel-scaling = <0>;
		qcom,calibration-type = "ratiometric";
		qcom,scale-function = <2>;
		qcom,hw-settle-time = <2>;
		qcom,fast-avg-setup = <0>;
	};

	chan@77 {
		label = "pa_therm1";
		reg = <0x77>;
		qcom,decimation = <0>;
		qcom,pre-div-channel-scaling = <0>;
		qcom,calibration-type = "ratiometric";
		qcom,scale-function = <2>;
		qcom,hw-settle-time = <2>;
		qcom,fast-avg-setup = <0>;
	};

	chan@78 {
		label = "quiet_therm";
		reg = <0x78>;
		qcom,decimation = <0>;
		qcom,pre-div-channel-scaling = <0>;
		qcom,calibration-type = "ratiometric";
		qcom,scale-function = <2>;
		qcom,hw-settle-time = <2>;
		qcom,fast-avg-setup = <0>;
	};
};

&i2c_9 {
	fts_i2c@49 {
		compatible = "stm,fts_ts";
		reg = <0x49>;
		interrupt-parent = <&tlmm>;
		interrupts = <123 0x0>;
		avdd-supply = <&max77838_l4>;
		vddo-supply = <&max77838_l2>;
		pinctrl-names = "tsp_active", "tsp_suspend";
		pinctrl-0 = <&tsp_int_active>;
		pinctrl-1 = <&tsp_int_suspend>;
		stm,irq-gpio = <&tlmm 123 0x0>;
		stm,tsp-coords = <4095 4095>;
		stm,grip_area = <512>;
		stm,i2c-pull-up = <1>;
		stm,tsp-project = "ZERO_E";
		stm,tsp-model = "G925";
		stm,bringup = <0>;
		stm,support_mskey;
		vdd_keyled-supply = <&pm8994_l18>;
		stm,support_gesture = <1>;
		stm,string-lib;
	};
};

&bluetooth {	/* same gpio with tsp-int: gpio46 */
	/delete-property/ pinctrl-names;
	/delete-property/ pinctrl-0;
};

&wcd9xxx_intc {
	qcom,gpio-connect = <&tlmm 79 0>;
};

&wcd_rst_gpio {
	compatible = "qcom,wcd-gpio-ctrl";
	qcom,cdc-rst-n-gpio = <&tlmm 74 0>;
	pinctrl-names = "aud_active", "aud_sleep";
	pinctrl-0 = <&cdc_reset_active>;
	pinctrl-1 = <&cdc_reset_sleep>;
};
	
&slim_msm {
	/delete-node/msm_dai_slim;

	tasha_codec {
		qcom,cdc-micbias2-mv = <2700>;
		qcom,cdc-dmic-sample-rate = <2400000>;
		/delete-node/swr_master;
	};
};

&pm8994_mpps {
	mpp@a100 {
		qcom,pin-num = <2>;		/* MPP 2 */
		qcom,mode = <1>;		/* Digital output */
		qcom,output-type = <0>;		/* CMOS logic */
		qcom,vin-sel = <2>;		/* S4 1.8V */
		qcom,src-sel = <0>;		/* Constant */
		qcom,master-en = <1>;		/* Enable GPIO */
		qcom,invert = <0>;
		status = "okay";
	};

	mpp@a300 {
		qcom,pin-num = <4>;		/* MPP 4 */
		qcom,mode = <4>;	/* AIN input */
		qcom,ain-route = <3>;	/* AMUX 8 */
		qcom,master-en = <1>;	/* Enable */
		qcom,src-sel = <0>;	/* Function constant */
		status = "okay";
	};

	mpp@a400 {
		qcom,pin-num = <5>;		/* MPP_05 */
		qcom,mode = <1>;		/* DIG_OUT */
		qcom,vin-sel = <2>;		/* 1.8V */
		qcom,master-en = <1>;		/* Enable */
		status = "okay";
	};

	mpp@a500 {
		qcom,pin-num = <6>;
		qcom,mode = <1>;		/* Digital output */
		qcom,output-type = <0>;		/* CMOS logic */
		qcom,vin-sel = <2>;		/* S4 1.8V */
		qcom,src-sel = <0>;		/* Constant */
		qcom,master-en = <1>;		/* Enable GPIO */
		qcom,invert = <0>;
		status = "okay";
	};

	mpp@a600 { /* 7 */
		qcom,pin-num = <7>;
		qcom,mode = <1>;		/* Digital output */
		qcom,output-type = <0>;		/* CMOS logic */
		qcom,vin-sel = <2>;		/* S4 1.8V */
		qcom,src-sel = <0>;		/* Constant */
		qcom,master-en = <1>;		/* Enable GPIO */
		qcom,invert = <0>;
		status = "okay";
	};

	mpp@a700 {
		qcom,pin-num = <8>;
		qcom,mode = <1>;		/* Digital output */
		qcom,output-type = <0>;		/* CMOS logic */
		qcom,vin-sel = <2>;		/* S4 1.8V */
		qcom,src-sel = <0>;		/* Constant */
		qcom,master-en = <1>;		/* Enable GPIO */
		qcom,invert = <0>;
		status = "okay";
	};
};

&pm8994_gpios {
	gpio@c000 { /* GPIO 1 */
		qcom,mode = <0>;
		qcom,pull = <0>;
		qcom,vin-sel = <2>;
		qcom,src-sel = <0>;
		qcom,master-en = <1>;
		status = "okay";
	};

	gpio@c100 { /* GPIO 2 */
		qcom,mode = <0>;		/* Digital in */
		qcom,pull = <5>;		/* QPNP_PIN_PULL_NO */
		qcom,vin-sel = <2>;		/* Logical 1 voltage value 1.8v */
		qcom,src-sel = <0>;		/* Constant */
		qcom,master-en = <1>;
		status = "okay";
	};

	gpio@c200 { /* GPIO 3 */
		qcom,mode = <0>;		/* Digital in */
		qcom,pull = <0>;		/* QPNP_PIN_PULL_UP_30 */
		qcom,vin-sel = <2>;		/* Logical 1 voltage value 1.8v */
		qcom,src-sel = <0>;		/* Constant */
		qcom,master-en = <1>;
		status = "okay";
	};

	gpio@c600 { /* GPIO 7 */
		qcom,mode = <0>;
		qcom,pull = <0>;
		qcom,vin-sel = <2>;
		qcom,src-sel = <0>;
		qcom,master-en = <1>;
		status = "okay";
	};

	gpio@c900 { /* GPIO 10 */
		qcom,mode = <0>;		/* Digital in */
		qcom,pull = <5>;		/* QPNP_PIN_PULL_NO */
		qcom,vin-sel = <2>;		/* Logical 1 voltage value 1.8v */
		qcom,src-sel = <2>;		/* Clock */
		qcom,master-en = <1>;
		status = "okay";
	};

	gpio@cb00 { /* GPIO 12 */
		qcom,mode = <0>;		/* Digital in */
		qcom,pull = <4>;		/* QPNP_PIN_PULL_DN */
		qcom,vin-sel = <2>;		/* Logical 1 voltage value 1.8v */
		qcom,src-sel = <0>;		/* Constant */
		status = "okay";
	};

	gpio@cc00 { /* GPIO 13 */
		qcom,mode = <0>;		/* Digital in */
		qcom,pull = <5>;		/* QPNP_PIN_PULL_NO */
		qcom,vin-sel = <2>;		/* Logical 1 voltage value 1.8v */
		qcom,src-sel = <0>;		/* Constant */
		status = "okay";
	};

	gpio@cf00 { /* GPIO 16 */
		qcom,mode = <1>;
		qcom,output-type = <0>;		/* CMOS logic */
		qcom,invert = <0>;		/* Output low initially */
		qcom,pull = <4>;
		qcom,vin-sel = <2>;
		qcom,src-sel = <3>;		/* Function 2 */
		qcom,master-en = <1>;
		qcom,out-strength = <2>;	/* Medium */
		status = "okay";
	};

	gpio@cd00 { /* GPIO 14 */
		qcom,mode = <0>;		/* Digital in */
		qcom,pull = <5>;		/* QPNP_PIN_PULL_NO */
		qcom,vin-sel = <2>;		/* Logical 1 voltage value 1.8v */
		qcom,src-sel = <0>;		/* Constant */
		status = "okay";
	};

	gpio@d000 { /* GPIO 17 */
		qcom,mode = <1>;
		qcom,output-type = <0>;		/* CMOS logic */
		qcom,invert = <0>;		/* Output low initially */
		qcom,pull = <4>;
		qcom,vin-sel = <2>;
		qcom,src-sel = <3>;		/* Function 2 */
		qcom,master-en = <1>;
		qcom,out-strength = <2>;	/* Medium */
		status = "okay";
	};
};

&pm8994_l18 {
	status = "okay";
	regulator-min-microvolt = <3300000>;
	regulator-max-microvolt = <3300000>;
	qcom,init-voltage = <3300000>;
};

&pm8994_l6 {
	status = "okay";
	regulator-min-microvolt = <1800000>;
	regulator-max-microvolt = <1800000>;
	qcom,init-voltage = <1800000>;
	regulator-boot-on;
};

&pm8994_l22 {
	status = "okay";
	regulator-min-microvolt = <3050000>;
	regulator-max-microvolt = <3050000>;
	qcom,init-voltage = <3050000>;
};

&pm8994_l27 {
	regulator-min-microvolt = <1100000>;
	regulator-max-microvolt = <1100000>;
	qcom,init-voltage = <1100000>;
	regulator-always-on;
	status = "okay";
};

&pm8994_l29 {
	regulator-min-microvolt = <2800000>;
	regulator-max-microvolt = <2800000>;
	qcom,init-voltage = <2800000>;
	regulator-always-on;
	status = "okay";
};

&pm8994_l14 {
	status = "okay";
	regulator-min-microvolt = <1800000>;
	regulator-max-microvolt = <1800000>;
	qcom,init-voltage = <1800000>;
	regulator-boot-on;
};

&pm8994_l19 {
	status = "okay";
	regulator-min-microvolt = <3300000>;
	regulator-max-microvolt = <3300000>;
	qcom,init-voltage = <3300000>;
};

&pm8004_mpps {
	mpp@a300 {
		qcom,mode = <1>;	/* Digital output */
		qcom,vin-sel = <2>;	/* 1.8 V */
		qcom,src-sel = <0>;	/* Constant */
		qcom,master-en = <1>;	/* Enable GPIO */
		status = "okay";
	};
};

#include "../../../../drivers/video/msm/mdss/samsung/S6E3HF4_AMB526JS01/dsi_panel_S6E3HF4_AMB526JS01_wqhd_octa_cmd.dtsi"
#include "../../../../drivers/video/msm/mdss/samsung/PBA_BOOTING_HD/dsi_panel_PBA_BOOTING_hd_video.dtsi"

&ss_dsi_panel_S6E3HF4_AMB526JS01_WQHD {
	qcom,panel-supply-entries {
		#address-cells = <1>;
		#size-cells = <0>;

		qcom,panel-supply-entry@0 {
			reg = <0>;
			qcom,supply-name = "vdd3";
			qcom,supply-min-voltage = <1800000>;
			qcom,supply-max-voltage = <1800000>;
			qcom,supply-enable-load = <100000>;
			qcom,supply-disable-load = <100>;
			qcom,supply-pre-on-sleep = <0>; /* unit is ms*/
			qcom,supply-post-on-sleep = <0>;
		};

		qcom,panel-supply-entry@1 {
			reg = <1>;
			qcom,supply-name = "vci";
			qcom,supply-min-voltage = <3000000>;
			qcom,supply-max-voltage = <3000000>;
			qcom,supply-enable-load = <100000>;
			qcom,supply-disable-load = <100>;
			qcom,supply-pre-on-sleep = <0>; /* unit is ms*/
			qcom,supply-post-on-sleep = <0>;
		};

		qcom,panel-supply-entry@2 {
			reg = <2>;
			qcom,supply-name = "vddr";
			qcom,supply-min-voltage = <1600000>;
			qcom,supply-max-voltage = <1600000>;
			qcom,supply-enable-load = <100000>;
			qcom,supply-disable-load = <100>;
			qcom,supply-pre-on-sleep = <0>; /* unit is ms*/
			qcom,supply-post-on-sleep = <0>;
		};
	};
};

&max77838_l1 {
	regulator-boot-on;
};

&max77838_l3 {
	regulator-boot-on;
};

&max77838_buck {
	regulator-boot-on;
};

&mdss_dsi0 {
	qcom,dsi-pref-prim-pan = <&ss_dsi_panel_S6E3HF4_AMB526JS01_WQHD>;

	qcom,platform-te-gpio = <&tlmm 10 0>;
	qcom,platform-reset-gpio = <&tlmm 143 0>;

	pinctrl-names = "mdss_default", "mdss_sleep";
	pinctrl-0 = <&mdss_dsi_active &mdss_te_active>;
	pinctrl-1 = <&mdss_dsi_suspend &mdss_te_suspend>;

	/* 	Panel Power
	*	vci -> s2mpb02_l17(needed to define here)
	*	vdd3 -> pm8994_lvs2(needed to define here)
	*	vddr -> s2mpb02_b1(needed to define here)
	*/
	vci-supply = <&max77838_l3>; /* 3.0V */
	vdd3-supply = <&max77838_l1>; /* 1.8V */
	vddr-supply = <&max77838_buck>; /* 1.6V */
};

&mdss_mdp {
	qcom,mdss-pref-prim-intf = "dsi";
	mdss_fb0: qcom,mdss_fb_primary {
		qcom,mdss-fb-split = <720 720>;
	};
};

&spmi_bus {
	qcom,pm8994@0 {
		qcom,power-on@800 {
			qcom,pon_1 {
				qcom,pon-type = <0>;
				qcom,support-reset = <0>;
				qcom,pull-up = <1>;
				linux,code = <116>;
				switch_powerkey;
			};

			qcom,pon_2 {
				qcom,pon-type = <1>;
				qcom,support-reset = <0>;
				qcom,pull-up = <1>;
				linux,code = <114>;
			};

			qcom,pon_3 {
				qcom,pon-type = <3>;
				qcom,support-reset = <1>;
				qcom,pull-up = <1>;
				qcom,s1-timer = <6720>;
				qcom,s2-timer = <1000>;
				qcom,s2-type = <8>;
				qcom,use-bark;
			};
		};
	};
};
